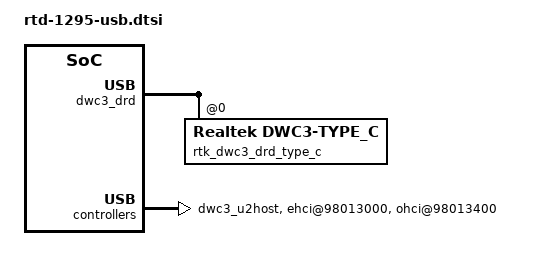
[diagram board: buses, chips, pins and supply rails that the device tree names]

/ {
	/include/ "rtd-129x-usb.dtsi"

	rtk_usb_power_manager@0 {
		compatible = "Realtek,usb-manager";

		status = "okay";
	};

	dwc3_drd: rtk_dwc3_drd@98013200 {
		compatible = "Realtek,dwc3";
		status = "okay";

		dwc3_drd@98020000 {
			dr_mode = "peripheral"; /*host, peripheral*/
		};

		rtk_dwc3_drd_type_c@0 {
			compatible = "Realtek,dwc3-type_c";
			drd_mode; //depend on dr_mode = "peripheral"
		};

	};

	dwc3_u2host: rtk_dwc3_u2host@98013E00 {
		compatible = "Realtek,dwc3";

		status = "okay";
	};

	ehci@98013000 {
		compatible = "Realtek,rtd129x-ehci";

		status = "okay";
	};

	ohci@98013400 {
		compatible = "Realtek,rtd129x-ohci";

		status = "okay";
	};
};
